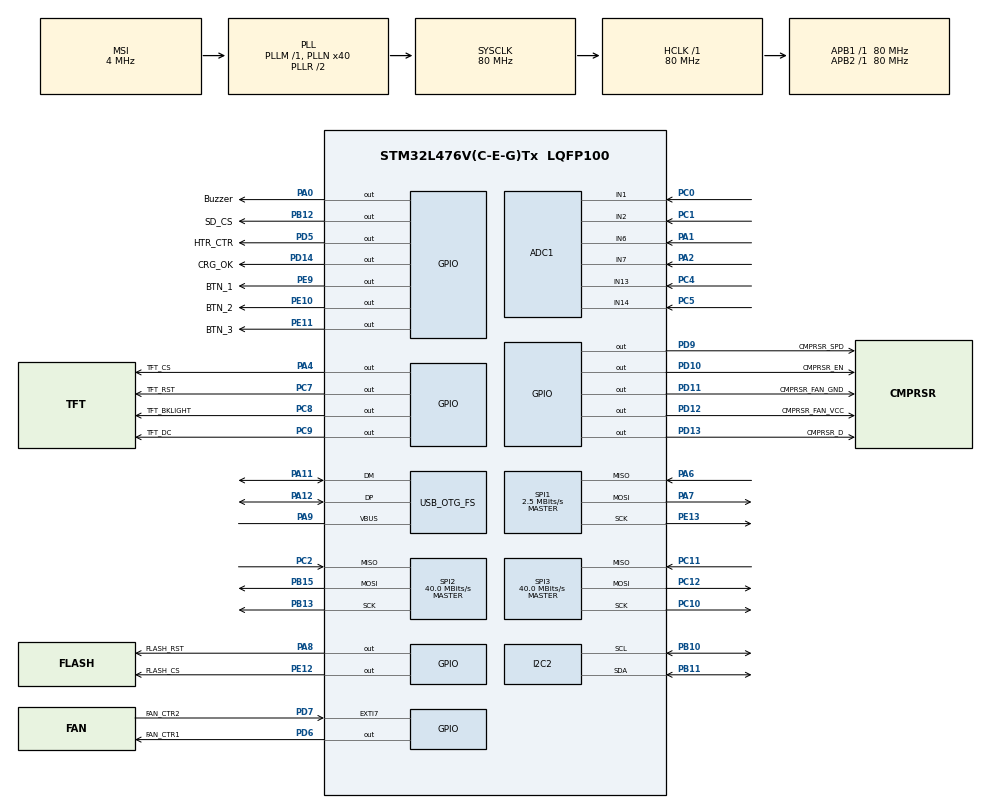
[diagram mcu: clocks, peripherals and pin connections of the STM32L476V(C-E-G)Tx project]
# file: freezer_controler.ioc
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ADC1.Channel-0\#ChannelRegularConversion=ADC_CHANNEL_2
ADC1.NbrOfConversionFlag=1
ADC1.OffsetNumber-0\#ChannelRegularConversion=ADC_OFFSET_NONE
ADC1.Rank-0\#ChannelRegularConversion=1
ADC1.SamplingTime-0\#ChannelRegularConversion=ADC_SAMPLETIME_2CYCLES_5
ADC1.master=1
CRC.CRCLength=CRC_POLYLENGTH_16B
CRC.DefaultInitValueUse=DEFAULT_INIT_VALUE_ENABLE
CRC.DefaultPolynomialUse=DEFAULT_POLYNOMIAL_DISABLE
CRC.InputDataInversionMode=CRC_INPUTDATA_INVERSION_BYTE
CRC.OutputDataInversionMode=CRC_OUTPUTDATA_INVERSION_DISABLE
Dma.Request0=SPI3_TX
Dma.SPI3_TX.0.Direction=DMA_MEMORY_TO_PERIPH
Dma.SPI3_TX.0.Instance=DMA2_Channel2
Dma.SPI3_TX.0.MemDataAlignment=DMA_MDATAALIGN_BYTE
Dma.SPI3_TX.0.MemInc=DMA_MINC_ENABLE
Dma.SPI3_TX.0.Mode=DMA_NORMAL
Dma.SPI3_TX.0.PeriphDataAlignment=DMA_PDATAALIGN_BYTE
Dma.SPI3_TX.0.PeriphInc=DMA_PINC_DISABLE
Dma.SPI3_TX.0.Priority=DMA_PRIORITY_LOW
FATFS._USE_LFN=1
I2C2.Timing=0x10909CEC
Mcu.Family=STM32L4
Mcu.Name=STM32L476V(C-E-G)Tx
Mcu.Package=LQFP100
NVIC.DMA2_Channel2_IRQn=true\:0\:0\:false\:false\:true\:false\:true\:true
NVIC.OTG_FS_IRQn=true\:0\:0\:false\:false\:true\:false\:true\:true
NVIC.PriorityGroup=NVIC_PRIORITYGROUP_4
PA0.GPIO_Label=Buzzer
PA0.Signal=GPIO_Output
PA1.Signal=ADCx_IN6
PA10.Signal=USB_OTG_FS_ID
PA11.Mode=Device_Only
PA11.Signal=USB_OTG_FS_DM
PA12.Mode=Device_Only
PA12.Signal=USB_OTG_FS_DP
PA2.Signal=ADCx_IN7
PA4.GPIO_Label=TFT_CS
PA4.PinState=GPIO_PIN_SET
PA4.Signal=GPIO_Output
PA6.Mode=Full_Duplex_Master
PA6.Signal=SPI1_MISO
PA7.Mode=Full_Duplex_Master
PA7.Signal=SPI1_MOSI
PA8.GPIO_Label=FLASH_RST
PA8.Signal=GPIO_Output
PA9.Mode=Activate_VBUS
PA9.Signal=USB_OTG_FS_VBUS
PB10.Mode=I2C
PB10.Signal=I2C2_SCL
PB11.Mode=I2C
PB11.Signal=I2C2_SDA
PB12.GPIO_Label=SD_CS
PB12.Signal=GPIO_Output
PB13.Mode=Full_Duplex_Master
PB13.Signal=SPI2_SCK
PB15.Mode=Full_Duplex_Master
PB15.Signal=SPI2_MOSI
PC0.Signal=ADCx_IN1
PC1.Signal=ADCx_IN2
PC10.Mode=Full_Duplex_Master
PC10.Signal=SPI3_SCK
PC11.Mode=Full_Duplex_Master
PC11.Signal=SPI3_MISO
PC12.Mode=Full_Duplex_Master
PC12.Signal=SPI3_MOSI
PC14-OSC32_IN\ (PC14).Mode=LSE-External-Oscillator
PC14-OSC32_IN\ (PC14).Signal=RCC_OSC32_IN
PC15-OSC32_OUT\ (PC15).Mode=LSE-External-Oscillator
PC15-OSC32_OUT\ (PC15).Signal=RCC_OSC32_OUT
PC2.Mode=Full_Duplex_Master
PC2.Signal=SPI2_MISO
PC4.Signal=ADCx_IN13
PC5.Signal=ADCx_IN14
PC7.GPIO_Label=TFT_RST
PC7.Signal=GPIO_Output
PC8.GPIO_Label=TFT_BKLIGHT
PC8.Signal=GPIO_Output
PC9.GPIO_Label=TFT_DC
PC9.Signal=GPIO_Output
PD10.GPIO_Label=CMPRSR_EN
PD10.Signal=GPIO_Output
PD11.GPIO_Label=CMPRSR_FAN_GND
PD11.Signal=GPIO_Output
PD12.GPIO_Label=CMPRSR_FAN_VCC
PD12.Signal=GPIO_Output
PD13.GPIO_Label=CMPRSR_D
PD13.Signal=GPIO_Output
PD14.GPIO_Label=CRG_OK
PD14.Signal=GPIO_Output
PD5.GPIO_Label=HTR_CTR
PD5.Signal=GPIO_Output
PD6.GPIO_Label=FAN_CTR1
PD6.Signal=GPIO_Output
PD7.GPIO_Label=FAN_CTR2
PD7.Signal=GPXTI7
PD9.GPIO_Label=CMPRSR_SPD
PD9.Signal=GPIO_Output
PE10.GPIO_Label=BTN_2
PE10.Signal=GPIO_Output
PE11.GPIO_Label=BTN_3
PE11.Signal=GPIO_Output
PE12.GPIO_Label=FLASH_CS
PE12.Signal=GPIO_Output
PE13.Mode=Full_Duplex_Master
PE13.Signal=SPI1_SCK
PE9.GPIO_Label=BTN_1
PE9.Signal=GPIO_Output
ProjectManager.HeapSize=0x200
ProjectManager.StackSize=0x400
ProjectManager.TargetToolchain=STM32CubeIDE
RCC.ADCFreq_Value=48000000
RCC.AHBFreq_Value=80000000
RCC.APB1Freq_Value=80000000
RCC.APB1TimFreq_Value=80000000
RCC.APB2Freq_Value=80000000
RCC.APB2TimFreq_Value=80000000
RCC.CortexFreq_Value=80000000
RCC.HCLKFreq_Value=80000000
RCC.HSE_VALUE=8000000
RCC.HSI_VALUE=16000000
RCC.MSI_VALUE=4000000
RCC.PLLN=40
RCC.PLLSAI1N=24
RCC.SYSCLKFreq_VALUE=80000000
RCC.SYSCLKSource=RCC_SYSCLKSOURCE_PLLCLK
RCC.USBFreq_Value=48000000
RCC.VCOOutputFreq_Value=160000000
SH.ADCx_IN1.0=ADC1_IN1,IN1-Single-Ended
SH.ADCx_IN13.0=ADC1_IN13,IN13-Single-Ended
SH.ADCx_IN14.0=ADC1_IN14,IN14-Single-Ended
SH.ADCx_IN2.0=ADC1_IN2,IN2-Single-Ended
SH.ADCx_IN6.0=ADC1_IN6,IN6-Single-Ended
SH.ADCx_IN7.0=ADC1_IN7,IN7-Single-Ended
SPI1.BaudRatePrescaler=SPI_BAUDRATEPRESCALER_32
SPI1.CalculateBaudRate=2.5 MBits/s
SPI1.DataSize=SPI_DATASIZE_8BIT
SPI1.Direction=SPI_DIRECTION_2LINES
SPI1.Mode=SPI_MODE_MASTER
SPI1.VirtualType=VM_MASTER
SPI2.BaudRatePrescaler=SPI_BAUDRATEPRESCALER_2
SPI2.CalculateBaudRate=40.0 MBits/s
SPI2.Direction=SPI_DIRECTION_2LINES
SPI2.Mode=SPI_MODE_MASTER
SPI2.VirtualType=VM_MASTER
SPI3.BaudRatePrescaler=SPI_BAUDRATEPRESCALER_2
SPI3.CalculateBaudRate=40.0 MBits/s
SPI3.DataSize=SPI_DATASIZE_8BIT
SPI3.Direction=SPI_DIRECTION_2LINES
SPI3.Mode=SPI_MODE_MASTER
SPI3.VirtualType=VM_MASTER
USB_DEVICE.CLASS_NAME_FS=MSC
USB_DEVICE.MSC_MEDIA_PACKET=4096
USB_DEVICE.USBD_MAX_STR_DESC_SIZ=4096
USB_DEVICE.VirtualMode=Msc
USB_DEVICE.VirtualModeFS=Msc_FS
USB_OTG_FS.VirtualMode=Device_Only
VP_CRC_VS_CRC.Mode=CRC_Activate
VP_FATFS_VS_Generic.Mode=User_defined
VP_RTC_VS_RTC_Activate.Mode=RTC_Enabled
VP_RTC_VS_RTC_Calendar.Mode=RTC_Calendar
VP_USB_DEVICE_VS_USB_DEVICE_MSC_FS.Mode=MSC_FS
board=custom

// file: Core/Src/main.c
/* USER CODE BEGIN Header */
/**
  ******************************************************************************
  * @file           : main.c
  * @brief          : Main program body
  ******************************************************************************
  * @attention
  *
  * Copyright (c) 2023 STMicroelectronics.
  * All rights reserved.
  *
  * This software is licensed under terms that can be found in the LICENSE file
  * in the root directory of this software component.
  * If no LICENSE file comes with this software, it is provided AS-IS.
  *
  ******************************************************************************
  */
/* USER CODE END Header */
#include "main.h"
#include "adc.h"
#include "crc.h"
#include "dma.h"
#include "fatfs.h"
#include "i2c.h"
#include "rtc.h"
#include "spi.h"
#include "usb_device.h"
#include "gpio.h"

/* USER CODE BEGIN Includes */
#include "lcd_ui.h"
#include "event.h"
/* USER CODE END Includes */

void SystemClock_Config(void);
void PeriphCommonClock_Config(void);

int main(void)
{

  /* MCU Configuration--------------------------------------------------------*/

  /* Reset of all peripherals, Initializes the Flash interface and the Systick. */
  HAL_Init();

  /* Configure the system clock */
  SystemClock_Config();

/* Configure the peripherals common clocks */
  PeriphCommonClock_Config();

  /* Initialize all configured peripherals */
  MX_GPIO_Init();
  MX_DMA_Init();
  MX_I2C2_Init();
  MX_SPI1_Init();
  MX_ADC1_Init();
  MX_SPI2_Init();
  MX_FATFS_Init();
  MX_SPI3_Init();
  MX_RTC_Init();
  MX_CRC_Init();
  MX_USB_DEVICE_Init();
  /* USER CODE BEGIN 2 */
  event_init();
  lcd_ui_init();

//  lcd_main_screen_screen(SPEAKER_MODE_ON, -20, POWER_MODE_DC, OPERATION_MODE_FREEZER, 80, BATTERY_STATE_CHARGING);
//  lcd_operation_mode_screen(OPERATION_MODE_FREEZER);
//  lcd_turn_off_unit(ON);
//  date_time_t date = {.year = 23, .month = 10, .day = 19, .hour = 12,.minute = 11};
//  lcd_setting_date_time(SETTING_DATE_TIME_MINUTE, &date);
//  lcd_service(SERVICE_CALIBRATION);
//  lcd_service_temperature(SERVICE_TEMPERATURE_FREEZER);
//  lcd_service_alarms(SERVICE_ALARMS_BACK);
//  lcd_service_data_calibration(SERVICE_CALIBRATION_TEMP_OFFSET);
//  lcd_service_temper_freezer_set_point(SERVICE_TEMPERATURE_FREEZER, -5);
//  lcd_service_temper_set_point_value(SERVICE_TEMPERATURE_FREEZER, -5);
//  lcd_service_alarm_temp(SERVICE_ALARM_TEMP_ALARM_DELAY);
//  lcd_service_alarm_temp_set_alarm_delay(3);
  lcd_ui_clear();
  lcd_service_alarms_warning(WARNING_MODE_FRIDGE, WARNING_TYPE_OVER_MAX_TEMP);
  lcd_ui_refesh();
  /* USER CODE END 2 */

  /* Infinite loop */
  /* USER CODE BEGIN WHILE */
  while (1)
  {
	 event_run_task();
    /* USER CODE END WHILE */

  }
}

void SystemClock_Config(void)
{
  RCC_OscInitTypeDef RCC_OscInitStruct = {0};
  RCC_ClkInitTypeDef RCC_ClkInitStruct = {0};

  /** Configure the main internal regulator output voltage
  */
  if (HAL_PWREx_ControlVoltageScaling(PWR_REGULATOR_VOLTAGE_SCALE1) != HAL_OK)
  {
    Error_Handler();
  }

  /** Configure LSE Drive Capability
  */
  HAL_PWR_EnableBkUpAccess();
  __HAL_RCC_LSEDRIVE_CONFIG(RCC_LSEDRIVE_LOW);

  /** Initializes the RCC Oscillators according to the specified parameters
  * in the RCC_OscInitTypeDef structure.
  */
  RCC_OscInitStruct.OscillatorType = RCC_OSCILLATORTYPE_LSI|RCC_OSCILLATORTYPE_LSE
                              |RCC_OSCILLATORTYPE_MSI;
  RCC_OscInitStruct.LSEState = RCC_LSE_ON;
  RCC_OscInitStruct.LSIState = RCC_LSI_ON;
  RCC_OscInitStruct.MSIState = RCC_MSI_ON;
  RCC_OscInitStruct.MSICalibrationValue = 0;
  RCC_OscInitStruct.MSIClockRange = RCC_MSIRANGE_6;
  RCC_OscInitStruct.PLL.PLLState = RCC_PLL_ON;
  RCC_OscInitStruct.PLL.PLLSource = RCC_PLLSOURCE_MSI;
  RCC_OscInitStruct.PLL.PLLM = 1;
  RCC_OscInitStruct.PLL.PLLN = 40;
  RCC_OscInitStruct.PLL.PLLP = RCC_PLLP_DIV7;
  RCC_OscInitStruct.PLL.PLLQ = RCC_PLLQ_DIV2;
  RCC_OscInitStruct.PLL.PLLR = RCC_PLLR_DIV2;
  if (HAL_RCC_OscConfig(&RCC_OscInitStruct) != HAL_OK)
  {
    Error_Handler();
  }

  /** Initializes the CPU, AHB and APB buses clocks
  */
  RCC_ClkInitStruct.ClockType = RCC_CLOCKTYPE_HCLK|RCC_CLOCKTYPE_SYSCLK
                              |RCC_CLOCKTYPE_PCLK1|RCC_CLOCKTYPE_PCLK2;
  RCC_ClkInitStruct.SYSCLKSource = RCC_SYSCLKSOURCE_PLLCLK;
  RCC_ClkInitStruct.AHBCLKDivider = RCC_SYSCLK_DIV1;
  RCC_ClkInitStruct.APB1CLKDivider = RCC_HCLK_DIV1;
  RCC_ClkInitStruct.APB2CLKDivider = RCC_HCLK_DIV1;

  if (HAL_RCC_ClockConfig(&RCC_ClkInitStruct, FLASH_LATENCY_4) != HAL_OK)
  {
    Error_Handler();
  }

  /** Enable MSI Auto calibration
  */
  HAL_RCCEx_EnableMSIPLLMode();
}

void PeriphCommonClock_Config(void)
{
  RCC_PeriphCLKInitTypeDef PeriphClkInit = {0};

  /** Initializes the peripherals clock
  */
  PeriphClkInit.PeriphClockSelection = RCC_PERIPHCLK_USB|RCC_PERIPHCLK_ADC;
  PeriphClkInit.AdcClockSelection = RCC_ADCCLKSOURCE_PLLSAI1;
  PeriphClkInit.UsbClockSelection = RCC_USBCLKSOURCE_PLLSAI1;
  PeriphClkInit.PLLSAI1.PLLSAI1Source = RCC_PLLSOURCE_MSI;
  PeriphClkInit.PLLSAI1.PLLSAI1M = 1;
  PeriphClkInit.PLLSAI1.PLLSAI1N = 24;
  PeriphClkInit.PLLSAI1.PLLSAI1P = RCC_PLLP_DIV7;
  PeriphClkInit.PLLSAI1.PLLSAI1Q = RCC_PLLQ_DIV2;
  PeriphClkInit.PLLSAI1.PLLSAI1R = RCC_PLLR_DIV2;
  PeriphClkInit.PLLSAI1.PLLSAI1ClockOut = RCC_PLLSAI1_48M2CLK|RCC_PLLSAI1_ADC1CLK;
  if (HAL_RCCEx_PeriphCLKConfig(&PeriphClkInit) != HAL_OK)
  {
    Error_Handler();
  }
}

void Error_Handler(void)
{
  __disable_irq();
  while (1)
  {
  }
}
